# GD32A72_A74x register map
File version: 1.0
CPU: CM7 r2p1, little endian, MPU, FPU, DSP, 4 interrupt priority bits
Registers are 32-bit, read-write, reset 0x0 unless marked. A register's access mark holds for its fields unless they carry their own. Offsets are from the block's base; [hi:lo] are bit positions; {n}, {i} and the like mark numbered series.

## TIMER0 — Advanced timer
Base 0x40012C00
Same registers: TIMER20 0x40000000, TIMER60 0x40001000, TIMER61 0x4000D000, TIMER63 0x4000D400, TIMER7 0x40013400, TIMER19 0x40015000, TIMER62 0x40016400
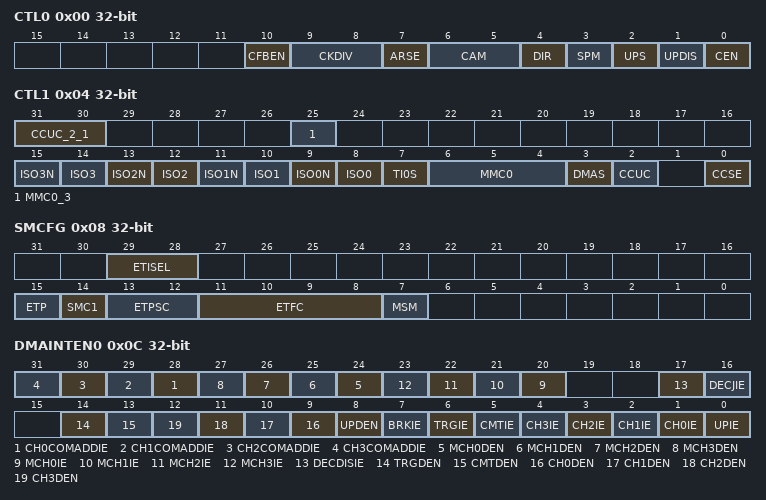
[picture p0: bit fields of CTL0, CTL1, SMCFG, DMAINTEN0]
0x00 CTL0 — Control register 0
  [10] CFBEN — Couter freeze in break mode enable
  [9:8] CKDIV — Clock division
  [7] ARSE — Auto-reload shadow enable
  [6:5] CAM — Counter align mode selection
  [4] DIR — Direction
  [3] SPM — Single pulse mode
  [2] UPS — Update source
  [1] UPDIS — Update disable
  [0] CEN — Counter enable
0x04 CTL1 — Control register 1
  [31:30] CCUC_2_1 — Refer to CCUC[0] bit
  [25] MMC0_3 — Refer to MMC0[2:0] description
  [2n+9] ISO{n}N (n=0..3) — Idle state of multi mode channel {n} complementary output
  [2n+8] ISO{n} (n=0..3) — Idle state of channel {n} output
  [7] TI0S — Channel 0 trigger input selection
  [6:4] MMC0 — Master mode control
  [3] DMAS — DMA request source selection
  [2] CCUC — Commutation control shadow register update control
  [0] CCSE — Commutation control shadow enable
0x08 SMCFG — Slave mode configuration register
  [29:28] ETISEL — TIMER0 external trigger select
  [15] ETP — External trigger polarity
  [14] SMC1 — Part of SMC is used to enable external clock mode 1
  [13:12] ETPSC — The prescaler of external trigger
  [11:8] ETFC — External trigger filter control
  [7] MSM — Master-slave mode
0x0C DMAINTEN0 — DMA and interrupt enable register 0
  [n+28] CH{n}COMADDIE (n=0..3) — Channel {n} additional compare interrupt enable
  [n+24] MCH{n}DEN (n=0..3) — Multi mode channel {n} capture/compare DMA request enable
  [n+20] MCH{n}IE (n=0..3) — Multi mode channel {n} capture/compare interrupt enable
  [17] DECDISIE — Quadrature decoder signal disconnection interrupt enable
  [16] DECJIE — Quadrature decoder signal jump (the two signals jump at the same time) interrupt enable
  [14] TRGDEN — Trigger DMA request enable
  [13] CMTDEN — Commutation DMA request enable
  [n+9] CH{n}DEN (n=0..3) — Channel {n} capture/compare DMA request enable
  [8] UPDEN — Update DMA request enable
  [7] BRKIE — Break interrupt enable
  [6] TRGIE — Trigger interrupt enable
  [5] CMTIE — Commutation interrupt enable
  [n+1] CH{n}IE (n=0..3) — Channel {n} capture/compare interrupt enable
  [0] UPIE — Update interrupt enable
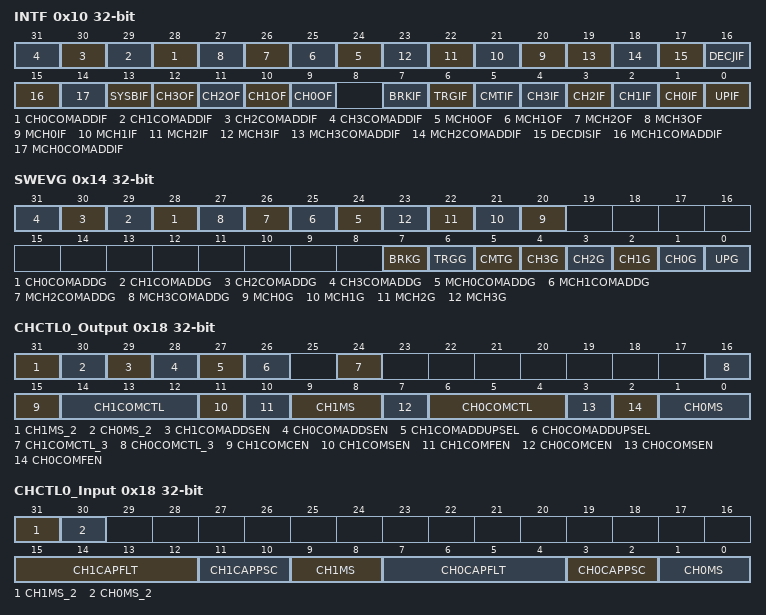
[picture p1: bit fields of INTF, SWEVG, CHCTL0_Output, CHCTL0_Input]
0x10 INTF — Interrupt flag register
  [n+28] CH{n}COMADDIF (n=0..3) — Channel {n} additional compare interrupt flag
  [n+24] MCH{n}OF (n=0..3) — Multi mode channel {n} over capture flag
  [n+20] MCH{n}IF (n=0..3) — Multi mode channel {n} capture/compare interrupt flag
  [19] MCH3COMADDIF — Multi mode channel 3 additional compare interrupt flag
  [18] MCH2COMADDIF — Multi mode channel 2 additional compare interrupt flag
  [17] DECDISIF — Quadrature decoder signal disconnection interrupt flag
  [16] DECJIF — Quadrature decoder signal jump (the two signals jump at the same time) interrupt flag
  [15] MCH1COMADDIF — Multi mode channel 1 additional compare interrupt flag
  [14] MCH0COMADDIF — Multi mode channel 0 additional compare interrupt flag
  [13] SYSBIF — System source break interrupt flag
  [n+9] CH{n}OF (n=0..3) — Channel {n} over capture flag
  [7] BRKIF — Break interrupt flag
  [6] TRGIF — Trigger interrupt flag
  [5] CMTIF — Channel commutation interrupt flag
  [n+1] CH{n}IF (n=0..3) — Channel {n} capture/compare interrupt flag
  [0] UPIF — Update interrupt flag
0x14 SWEVG wo — Software event generation register
  [n+28] CH{n}COMADDG (n=0..3) — Channel {n} additional compare event generation
  [n+24] MCH{n}COMADDG (n=0..3) — Multi mode Channel {n} additional compare event generation
  [n+20] MCH{n}G (n=0..3) — Multi mode channel {n} capture or compare event generation
  [7] BRKG — Break event generation
  [6] TRGG — Trigger event generation
  [5] CMTG — Channel commutation event generation
  [n+1] CH{n}G (n=0..3) — Channel {n} capture or compare event generation
  [0] UPG — Update event generation
0x18 CHCTL0_Output — Channel control register 0 (output mode)
  [31] CH1MS_2 — Channel 1 I/O mode selection
  [30] CH0MS_2 — Channel 0 I/O mode selection
  [29] CH1COMADDSEN — Channel 1 additional compare output shadow enable
  [28] CH0COMADDSEN — Channel 0 additional compare output shadow enable
  [27] CH1COMADDUPSEL — Refer to CH0COMADDUPSEL
  [26] CH0COMADDUPSEL — Update selection of channel 0 additional compare value
  [24] CH1COMCTL_3 — Refer to CH1COMCTL[2:0]
  [16] CH0COMCTL_3 — Refer to CH0COMCTL[2:0]
  [15] CH1COMCEN — Channel 1 output compare clear enable
  [14:12] CH1COMCTL — Channel 1 compare output control
  [11] CH1COMSEN — Channel 1 output compare shadow enable
  [10] CH1COMFEN — Channel 1 output compare fast enable
  [9:8] CH1MS — Channel 1 mode selection
  [7] CH0COMCEN — Channel 0 output compare clear enable
  [6:4] CH0COMCTL — Channel 0 compare output control
  [3] CH0COMSEN — Channel 0 compare output shadow enable
  [2] CH0COMFEN — Channel 0 output compare fast enable
  [1:0] CH0MS — Channel 0 I/O mode selection
0x18 CHCTL0_Input (alternate view of CHCTL0_Output) — Channel control register 0 (input mode)
  [31] CH1MS_2 — Channel 1 I/O mode selection
  [30] CH0MS_2 — Channel 0 I/O mode selection
  [15:12] CH1CAPFLT — Channel 1 input capture filter control
  [11:10] CH1CAPPSC — Channel 1 input capture prescaler
  [9:8] CH1MS — Channel 1 mode selection
  [7:4] CH0CAPFLT — Channel 0 input capture filter control
  [3:2] CH0CAPPSC — Channel 0 input capture prescaler
  [1:0] CH0MS — Channel 0 I/O mode selection
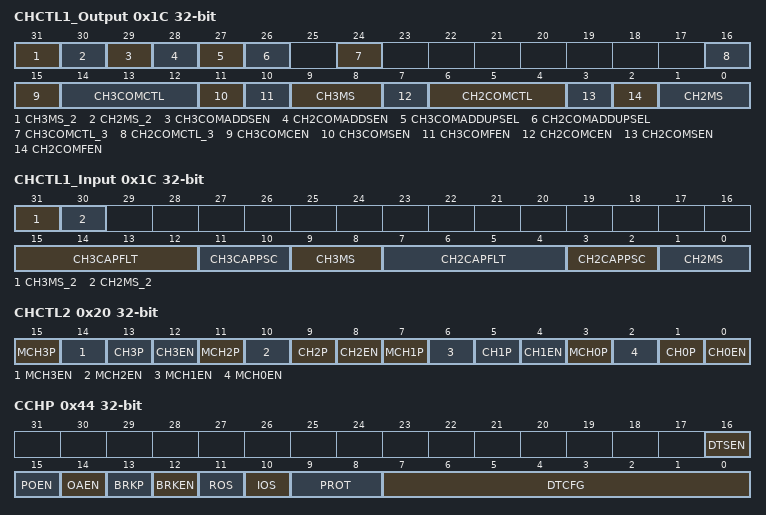
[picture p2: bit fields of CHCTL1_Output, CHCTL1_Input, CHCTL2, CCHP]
0x1C CHCTL1_Output — Channel control register 1 (output mode)
  [31] CH3MS_2 — Channel 3 I/O mode selection
  [30] CH2MS_2 — Channel 2 I/O mode selection
  [29] CH3COMADDSEN — Channel 3 additional compare output shadow enable
  [28] CH2COMADDSEN — Channel 2 additional compare output shadow enable
  [27] CH3COMADDUPSEL — Refer to CH0COMADDUPSEL
  [26] CH2COMADDUPSEL — Update selection of channel 2 additional compare value
  [24] CH3COMCTL_3 — Refer to CH3COMCTL[2:0]
  [16] CH2COMCTL_3 — Refer to CH2COMCTL[2:0]
  [15] CH3COMCEN — Channel 3 output compare clear enable
  [14:12] CH3COMCTL — Channel 3 compare output control
  [11] CH3COMSEN — Channel 3 output compare shadow enable
  [10] CH3COMFEN — Channel 3 output compare fast enable
  [9:8] CH3MS — Channel 3 mode selection
  [7] CH2COMCEN — Channel 2 output compare clear enable
  [6:4] CH2COMCTL — Channel 1 output compare shadow enable
  [3] CH2COMSEN — Channel 2 output compare shadow enable
  [2] CH2COMFEN — Channel 2 output compare fast enable
  [1:0] CH2MS — Channel 2 I/O mode selection
0x1C CHCTL1_Input (alternate view of CHCTL1_Output) — Channel control register 1 (input mode)
  [31] CH3MS_2 — Channel 3 I/O mode selection
  [30] CH2MS_2 — Channel 2 I/O mode selection
  [15:12] CH3CAPFLT — Channel 3 input capture filter control
  [11:10] CH3CAPPSC — Channel 3 input capture prescaler
  [9:8] CH3MS — Channel 3 mode selection
  [7:4] CH2CAPFLT — Channel 2 input capture filter control
  [3:2] CH2CAPPSC — Channel 2 input capture prescaler
  [1:0] CH2MS — Channel 2 I/O mode selection
0x20 CHCTL2 — Channel control register 2
  [15] MCH3P — Multi mode channel 3 capture/compare polarity
  [14] MCH3EN — Multi mode channel 3 capture/compare enable
  [4n+1] CH{n}P (n=0..3) — Channel {n} capture/compare polarity
  [4n] CH{n}EN (n=0..3) — Channel {n} capture/compare enable
  [11] MCH2P — Multi mode channel 2 output polarity
  [10] MCH2EN — Multi mode channel 2 output enable
  [7] MCH1P — Multi mode channel 1 output polarity
  [6] MCH1EN — Multi mode channel 1 output enable
  [3] MCH0P — Multi mode channel 0 output polarity
  [2] MCH0EN — Multi mode channel 0 capture/compare enable
0x24 CNT — Counter register
  [15:0] CNT — This bit-field indicates the current counter value
0x28 PSC — Prescaler register
  [15:0] PSC — Prescaler value of the counter clock
0x2C CAR — Counter auto reload register
  [15:0] CARL — Counter auto reload value
0x30 CREP — Counter repetition register
  [7:0] CREP — Counter repetition value
{0x34+4i} CH{i}CV (i=0..3) — Channel {i} capture/compare value register
  [15:0] CH{i}VAL — Capture/compare value of channel {i}
0x44 CCHP — Complementary channel protection register
  [16] DTSEN — Deadtime shadow is enabled
  [15] POEN — Primary output enable
  [14] OAEN — Output automatic enable
  [13] BRKP — BRKINx(x = 0..3) input signals polarity
  [12] BRKEN — BRKINx(x = 0..3) input signals enable
  [11] ROS — Run mode off-state enable
  [10] IOS — Idle mode off-state enable
  [9:8] PROT — Complementary register protect control
  [7:0] DTCFG — Dead time configuration
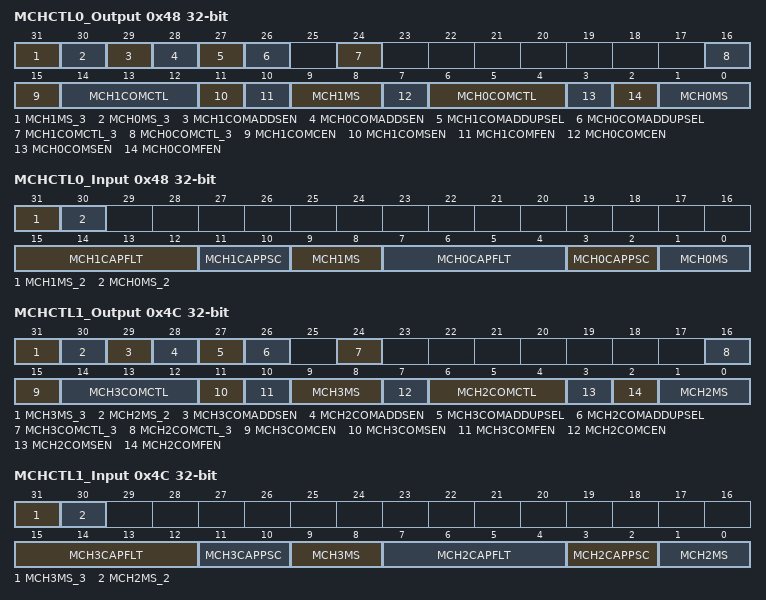
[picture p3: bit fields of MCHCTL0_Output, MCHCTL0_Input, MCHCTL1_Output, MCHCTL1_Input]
0x48 MCHCTL0_Output — Multi mode channel control register 0 (output mode)
  [31] MCH1MS_3 — Multi mode channel 1 I/O mode selection
  [30] MCH0MS_3 — Multi mode channel 0 I/O mode selection
  [29] MCH1COMADDSEN — Multi mode channel 1 output additional compare shadow enable
  [28] MCH0COMADDSEN — Multi mode channel 0 output additional compare shadow enable
  [27] MCH1COMADDUPSEL — Update selection of multi mode channel 1 additional compare value
  [26] MCH0COMADDUPSEL — Update selection of multi mode channel 0 additional compare value
  [24] MCH1COMCTL_3 — Refer to MCH1COMCTL[2:0]
  [16] MCH0COMCTL_3 — Refer to MCH0COMCTL[2:0]
  [15] MCH1COMCEN — Multi mode channel 1 output compare clear enable
  [14:12] MCH1COMCTL — Multi mode channel 1 compare output control
  [11] MCH1COMSEN — Multi mode channel 1 output compare shadow enable
  [10] MCH1COMFEN — Multi mode channel 1 output compare fast enable
  [9:8] MCH1MS — Multi mode channel 1 I/O mode selection
  [7] MCH0COMCEN — Multi mode channel 0 output compare clear enable
  [6:4] MCH0COMCTL — Multi mode channel 0 compare output control
  [3] MCH0COMSEN — Multi mode channel 0 output compare shadow enable
  [2] MCH0COMFEN — Multi mode Channel 0 output compare fast enable
  [1:0] MCH0MS — Multi mode channel 0 I/O mode selection
0x48 MCHCTL0_Input (alternate view of MCHCTL0_Output) — Multi mode channel control register 0 (input mode)
  [31] MCH1MS_2 — Multi mode channel 1 I/O mode selection
  [30] MCH0MS_2 — Multi mode channel 0 I/O mode selection
  [15:12] MCH1CAPFLT — Multi mode channel 1 input capture filter control
  [11:10] MCH1CAPPSC — Multi mode channel 1 input capture prescaler
  [9:8] MCH1MS — Multi mode channel 1 I/O mode selection
  [7:4] MCH0CAPFLT — Multi mode channel 0 input capture filter control
  [3:2] MCH0CAPPSC — Multi mode channel 0 input capture prescaler
  [1:0] MCH0MS — Multi mode channel 0 I/O mode selection
0x4C MCHCTL1_Output — Multi mode channel control register 1 (output mode)
  [31] MCH3MS_3 — Multi mode channel 1 I/O mode selection
  [30] MCH2MS_2 — Multi mode channel 0 I/O mode selection
  [29] MCH3COMADDSEN — Multi mode channel 3 output additional compare shadow enable
  [28] MCH2COMADDSEN — Multi mode channel 2 output additional compare shadow enable
  [27] MCH3COMADDUPSEL — Update selection of multi mode channel 3 additional compare value
  [26] MCH2COMADDUPSEL — Update selection of multi mode channel 2 additional compare value
  [24] MCH3COMCTL_3 — Refer to MCH0COMCTL[2:0]
  [16] MCH2COMCTL_3 — Refer to MCH0COMCTL[2:0]
  [15] MCH3COMCEN — Multi mode channel 3 output compare clear enable
  [14:12] MCH3COMCTL — Multi mode channel 3 compare output control
  [11] MCH3COMSEN — Multi mode channel 3 output compare shadow enable
  [10] MCH3COMFEN — Multi mode Channel 3 output compare fast enable
  [9:8] MCH3MS — Multi mode channel 3 I/O mode selection
  [7] MCH2COMCEN — Multi mode channel 2 output compare clear enable
  [6:4] MCH2COMCTL — Multi mode channel 2 compare output control
  [3] MCH2COMSEN — Multi mode channel 2 output compare shadow enable
  [2] MCH2COMFEN — Multi mode Channel 2 output compare fast enable
  [1:0] MCH2MS — Multi mode channel 2 I/O mode selection
0x4C MCHCTL1_Input (alternate view of MCHCTL1_Output) — Multi mode channel control register 1 (input mode)
  [31] MCH3MS_3 — Multi mode channel 1 I/O mode selection
  [30] MCH2MS_2 — Multi mode channel 0 I/O mode selection
  [15:12] MCH3CAPFLT — Multi mode channel 3 input capture filter control
  [11:10] MCH3CAPPSC — Multi mode channel 3 input capture prescaler
  [9:8] MCH3MS — Multi mode channel 3 I/O mode selection
  [7:4] MCH2CAPFLT — Multi mode channel 2 input capture filter control
  [3:2] MCH2CAPPSC — Multi mode channel 2 input capture prescaler
  [1:0] MCH2MS — Multi mode channel 2 I/O mode selection
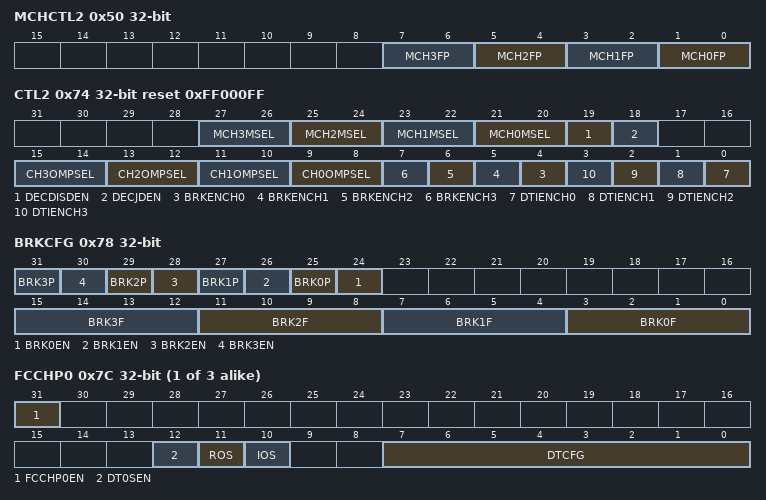
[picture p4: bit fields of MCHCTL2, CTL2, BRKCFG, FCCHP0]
0x50 MCHCTL2 — Multi mode channel control register 2
  [2n+1:2n] MCH{n}FP (n=0..3) — Multi mode channel {n} capture/compare free polarity
{0x54+4i} MCH{i}CV (i=0..3) — Multi mode channel {i} capture/compare value register
  [15:0] MCH{i}VAL — Capture/compare value of multi mode channel {i}
{0x64+4i} CH{i}CV_ADD (i=0..3) — Channel {i} additional capture/compare value register
  [15:0] CH{i}VAL_ADD — Additional capture/compare value of channel {i}
0x74 CTL2 reset 0xFF000FF — Control register 2
  [2n+21:2n+20] MCH{n}MSEL (n=0..3) — Multi mode channel {n} mode select
  [19] DECDISDEN — Quadrature decoder signal disconnection detection enable
  [18] DECJDEN — Quadrature decoder signal jump (the two signals jump at the same time) detection enable
  [2n+9:2n+8] CH{n}OMPSEL (n=0..3) — Channel {n} output match pulse select
  [n+4] BRKENCH{n} (n=0..3) — Break control enable for channel {n}
  [n] DTIENCH{n} (n=0..3) — Dead time inserted enable for channel {n}
0x78 BRKCFG — Break configuration register
  [2n+25] BRK{n}P (n=0..3) — BRKIN{n} input signal polarity
  [2n+24] BRK{n}EN (n=0..3) — BRKIN{n} input signal enable
  [4n+3:4n] BRK{n}F (n=0..3) — BRKIN{n} input signal filter
{0x7C+4i} FCCHP{i} (i=0..2) — Free complementary channel protection register {i}
  [31] FCCHP{i}EN — Free complementary channel protection register {i} enable
  [12] DT{i}SEN — Channel {i} deadtime shadow is enabled
  [11] ROS — Run mode off-state configure
  [10] IOS — Idle mode off-state configure
  [7:0] DTCFG — Dead time configure
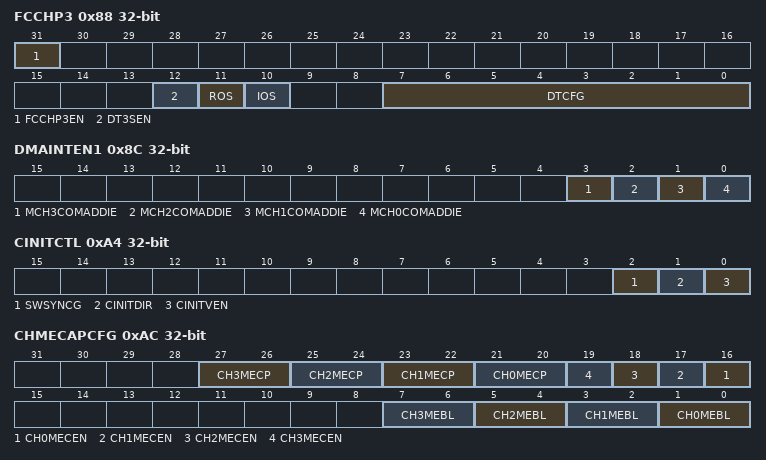
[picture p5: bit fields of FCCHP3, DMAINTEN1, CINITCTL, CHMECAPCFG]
0x88 FCCHP3 — Free complementary channel protection register 3
  [31] FCCHP3EN — Free complementary channel protection register 0 enable
  [12] DT3SEN — Channel 3 deadtime shadow is enabled
  [11] ROS — Run mode off-state configure
  [10] IOS — Idle mode off-state configure
  [7:0] DTCFG — Dead time configure
0x8C DMAINTEN1 — DMA and interrupt enable register1
  [3] MCH3COMADDIE — Refer to MCH0COMADDIE bit
  [2] MCH2COMADDIE — Refer to MCH0COMADDIE bit
  [1] MCH1COMADDIE — Refer to MCH0COMADDIE bit
  [0] MCH0COMADDIE — Multi mode Channel 0 additional compare interrupt enable
{0x90+4i} MCH{i}CV_ADD (i=0..3) — Multi mode channel {i} additional capture/compare value register
  [15:0] MCH{i}CVAL_ADD — Additional capture/compare value of multi mode channel {i}
0xA0 WDGPER reset 0xFFFFFFFF — Watchdog counter period register
  [31:0] WDGPER — Watchdog counter period value
0xA4 CINITCTL — Counter initial control register
  [2] SWSYNCG — Software synchronization event generation
  [1] CINITDIR — Counter initial count direction
  [0] CINITVEN — Counter initial value register enable
0xA8 CINITV — Counter initial value register
  [15:0] CINITVAL — Counter initial value
0xAC CHMECAPCFG — Channel multi-edge capture configuration register
  [27:26] CH3MECP — Channel 3 multi-edge capture polarity
  [25:24] CH2MECP — Channel 2 multi-edge capture polarity
  [23:22] CH1MECP — Channel 1 multi-edge capture polarity
  [21:20] CH0MECP — Channel 0 multi edge capture polarity
  [n+16] CH{n}MECEN (n=0..3) — Channel {n} multi edge capture enable
  [2n+1:2n] CH{n}MEBL (n=0..3) — Channel {n} multi edge buffer level
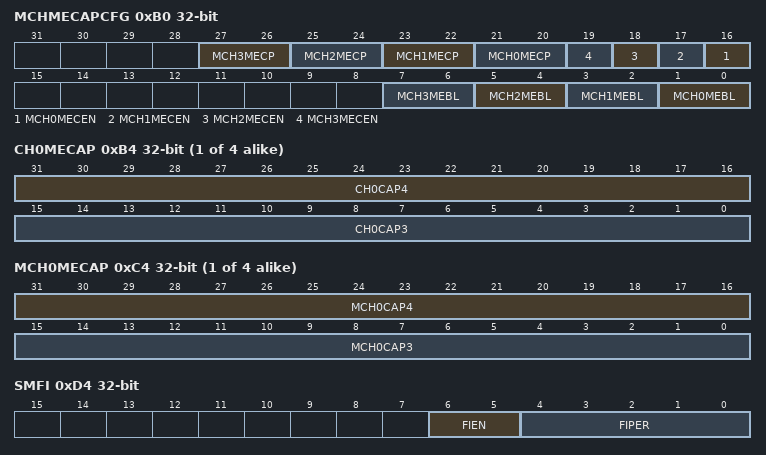
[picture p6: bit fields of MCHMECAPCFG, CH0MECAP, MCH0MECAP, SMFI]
0xB0 MCHMECAPCFG — Multi mode channel multi-edge capture configuration register
  [27:26] MCH3MECP — Multi mode channel 3 multi-edge capture polarity
  [25:24] MCH2MECP — Multi mode channel 2 multi-edge capture polarity
  [23:22] MCH1MECP — Multi mode channel 1 multi-edge capture polarity
  [21:20] MCH0MECP — Multi mode channel 0 multi edge capture polarity
  [n+16] MCH{n}MECEN (n=0..3) — Multi mode channel {n} multi edge capture enable
  [2n+1:2n] MCH{n}MEBL (n=0..3) — Multi mode channel {n} multi edge buffer level
{0xB4+4i} CH{i}MECAP ro (i=0..3) — Channel {i} multi-edge capture register
  [31:16] CH{i}CAP4 — Must be kept at reset value
  [15:0] CH{i}CAP3 — Channel {i} captures 4 count values
{0xC4+4i} MCH{i}MECAP ro (i=0..3) — Multi mode channel {i} multi-edge capture register
  [31:16] MCH{i}CAP4 — Must be kept at reset value
  [15:0] MCH{i}CAP3 — Multi mode channel {i} captures 4 count values
0xD4 SMFI — Safety mechanism fault injection register
  [6:5] FIEN — Fault injection enable
  [4:0] FIPER — Fault injection period value
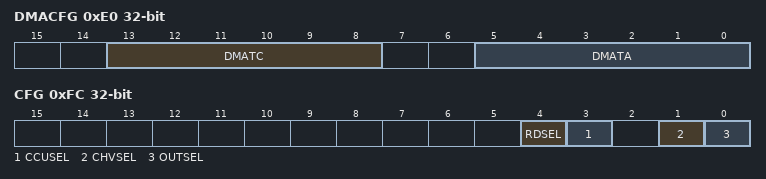
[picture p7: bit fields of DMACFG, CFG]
0xE0 DMACFG — DMA configuration register
  [13:8] DMATC — DMA transfer count
  [5:0] DMATA — DMA transfer access start address
0xE4 DMATB — DMA transfer buffer register
  [15:0] DMATB — DMA transfer buffer
0xFC CFG — Configuration register
  [4] RDSEL — This bit determines the value of TIMER0_PSC, TIMER0_CAR, TIMER0_CHyCV, TIMER0_MCHyCV, TIMER0_CHyCV_ADD when reading the register
  [3] CCUSEL — Commutation control shadow register update selection
  [1] CHVSEL — Write CHxVAL register selection bit
  [0] OUTSEL — The output value selection bit
